AUTOSAR XML (schema 4-2-2)
package /CDD_CORE2
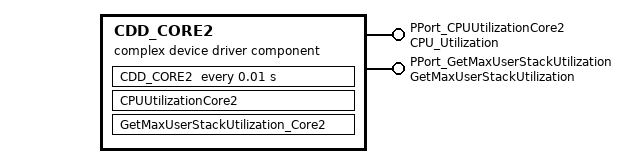
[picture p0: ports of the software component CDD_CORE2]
  complex device driver sw component type CDD_CORE2
    provide port PPort_CPUUtilizationCore2: provided-interface=CPU_Utilization
    provide port PPort_GetMaxUserStackUtilization: provided-interface=GetMaxUserStackUtilization
    behavior SwcInternalBehavior
      operation invoked event OperationInvokedEvent_0: start-on-event=CPUUtilizationCore2, operation=PPort_CPUUtilizationCore2.CPU_Utilization
      timing event TimingEvent_0: start-on-event=CDD_CORE2, period=0.01
      operation invoked event OperationInvokedEvent_1: start-on-event=GetMaxUserStackUtilization_Core2, operation=PPort_GetMaxUserStackUtilization.GetMaxUserStackUtilization
      runnable CPUUtilizationCore2: symbol=CPUUtilizationCore2_func
      runnable CDD_CORE2: symbol=CDD_CORE2_func
      runnable GetMaxUserStackUtilization_Core2: symbol=GetMaxUserStackUtilization_Core2_func
